# STM32H755_CM4 register map
File version: 2.5
CPU: CM4 r0p1, little endian, MPU, FPU, 4 interrupt priority bits
Registers are 32-bit, read-write, reset 0x0 unless marked. A register's access mark holds for its fields unless they carry their own. Offsets are from the block's base; [hi:lo] are bit positions; lines under a group give offsets from that group; {n}, {i} and the like mark numbered series; 'fields as' and 'values as' point back to an identical list.

## TIM6 — Basic timers
Base 0x40001000
Same registers: TIM7 0x40001400
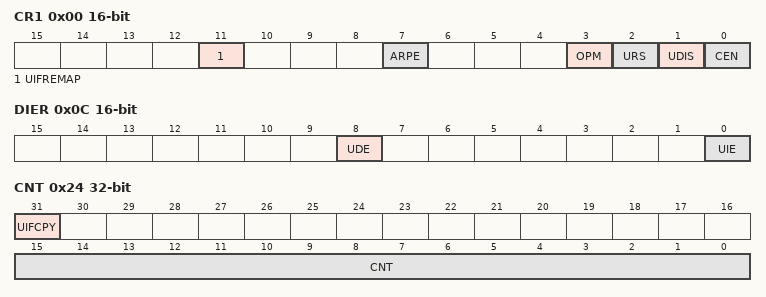
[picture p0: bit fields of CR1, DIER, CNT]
0x00 CR1 16-bit — control register 1
  [11] UIFREMAP — UIF status bit remapping
  [7] ARPE — Auto-reload preload enable
    0=Disabled (TIMx_APRR register is not buffered); 1=Enabled (TIMx_APRR register is buffered)
  [3] OPM — One-pulse mode
    0=Disabled (Counter is not stopped at update event); 1=Enabled (Counter stops counting at the next update event (clearing the CEN bit))
  [2] URS — Update request source
    0=AnyEvent (Any of counter overflow/underflow, setting UG, or update through slave mode, generates an update interrupt or DMA request); 1=CounterOnly (Only counter overflow/underflow generates an update interrupt or DMA request)
  [1] UDIS — Update disable
    0=Enabled (Update event enabled); 1=Disabled (Update event disabled)
  [0] CEN — Counter enable
    0=Disabled (Counter disabled); 1=Enabled (Counter enabled)
0x04 CR2 16-bit — control register 2
  [6:4] MMS — Master mode selection
    0=Reset (Use UG bit from TIMx_EGR register); 1=Enable (Use CNT bit from TIMx_CEN register); 2=Update (Use the update event)
0x0C DIER 16-bit — DMA/Interrupt enable register
  [8] UDE — Update DMA request enable
    0=Disabled (Update DMA request disabled); 1=Enabled (Update DMA request enabled)
  [0] UIE — Update interrupt enable
    0=Disabled (Update interrupt disabled); 1=Enabled (Update interrupt enabled)
0x10 SR 16-bit — status register
  [0] UIF write-0-clears — Update interrupt flag
    on read: 0=NoUpdateOccurred; 1=UpdatePending (Update interrupt pending) | on write: 0=Clear flag
0x14 EGR wo — event generation register
  [0] UG — Update generation
    1=Update (Re-initializes the timer counter and generates an update of the registers.)
0x24 CNT — counter
  [31] UIFCPY — UIF Copy
  [15:0] CNT — Low counter value
0x24 CNT16 16-bit (alternate view of CNT) — 16-bit counter register
  [15:0] CNT — counter value
0x28 PSC 16-bit — prescaler
  [15:0] PSC — Prescaler value
0x2C ARR 16-bit reset 0xFFFF — auto-reload register
  [15:0] ARR — Low Auto-reload value

## DBGMCU — Microcontroller Debug Unit
Base 0x5C001000
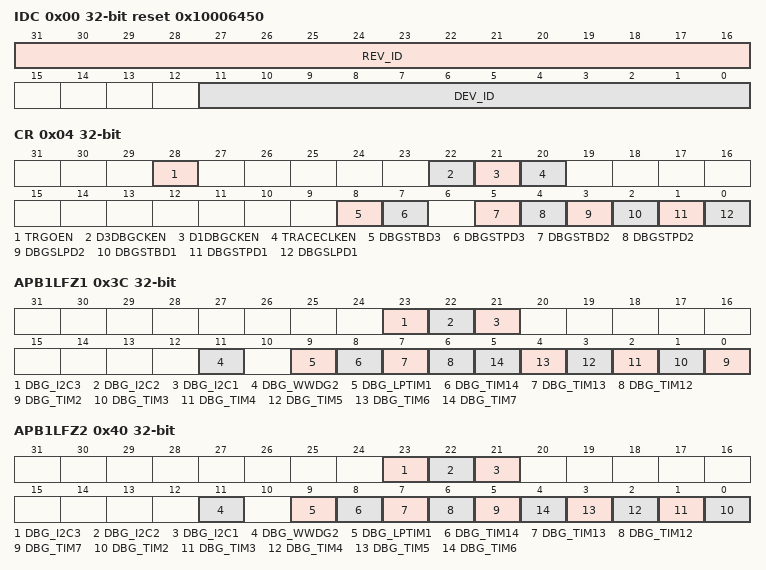
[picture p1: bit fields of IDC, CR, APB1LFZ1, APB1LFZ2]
0x00 IDC ro reset 0x10006450 — DBGMCU Identity Code Register
  [31:16] REV_ID — Revision
  [11:0] DEV_ID — Device ID
0x04 CR — DBGMCU Configuration Register
  [28] TRGOEN — External trigger output enable
  [22] D3DBGCKEN — D3 debug clock enable
  [21] D1DBGCKEN — D1 debug clock enable
  [20] TRACECLKEN — Trace port clock enable
  [8] DBGSTBD3 — Allow debug in D3 Standby mode
  [7] DBGSTPD3 — Allow debug in D3 Stop mode
  [5] DBGSTBD2 — Allow D2 domain debug in Standby mode
  [4] DBGSTPD2 — Allow D2 domain debug in Stop mode
  [3] DBGSLPD2 — Allow D2 domain debug in Sleep mode
  [2] DBGSTBD1 — Allow D1 domain debug in Standby mode
  [1] DBGSTPD1 — Allow D1 domain debug in Stop mode
  [0] DBGSLPD1 — Allow D1 domain debug in Sleep mode
0x34 APB3FZ1 — DBGMCU APB3 peripheral freeze register CPU1
  [6] WWDG1 — WWDG1 stop in debug
0x38 APB3FZ2 — DBGMCU APB3 peripheral freeze register CPU2
  [6] WWDG1 — WWDG1 stop in debug
0x3C APB1LFZ1 — DBGMCU APB1L peripheral freeze register
  [23] DBG_I2C3 — I2C3 SMBUS timeout stop in debug
  [22] DBG_I2C2 — I2C2 SMBUS timeout stop in debug
  [21] DBG_I2C1 — I2C1 SMBUS timeout stop in debug
  [11] DBG_WWDG2 — WWDG2 stop in debug
  [9] DBG_LPTIM1 — LPTIM1 stop in debug
  [8] DBG_TIM14 — TIM14 stop in debug
  [7] DBG_TIM13 — TIM13 stop in debug
  [6] DBG_TIM12 — TIM12 stop in debug
  [n-2] DBG_TIM{n} (n=2..7) — TIM{n} stop in debug
0x40 APB1LFZ2 — DBGMCU APB1L peripheral freeze register CPU2
  [23] DBG_I2C3 — I2C3 SMBUS timeout stop in debug
  [22] DBG_I2C2 — I2C2 SMBUS timeout stop in debug
  [21] DBG_I2C1 — I2C1 SMBUS timeout stop in debug
  [11] DBG_WWDG2 — WWDG2 stop in debug
  [9] DBG_LPTIM1 — LPTIM1 stop in debug
  [8] DBG_TIM14 — TIM14 stop in debug
  [7] DBG_TIM13 — TIM13 stop in debug
  [6] DBG_TIM12 — TIM12 stop in debug
  [5] DBG_TIM7 — TIM4 stop in debug
  [n-2] DBG_TIM{n} (n=2..6) — TIM{n} stop in debug
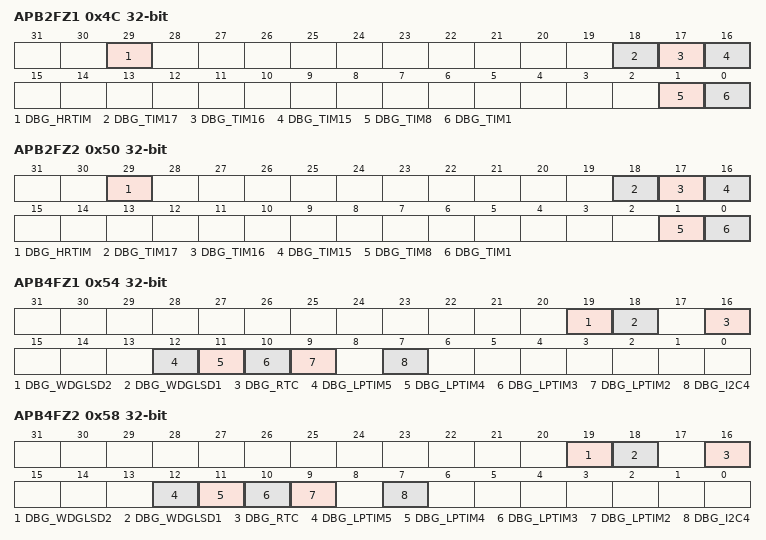
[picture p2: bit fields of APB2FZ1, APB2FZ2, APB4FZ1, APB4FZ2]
0x4C APB2FZ1 — DBGMCU APB2 peripheral freeze register
  [29] DBG_HRTIM — HRTIM stop in debug
  [18] DBG_TIM17 — TIM17 stop in debug
  [17] DBG_TIM16 — TIM16 stop in debug
  [16] DBG_TIM15 — TIM15 stop in debug
  [1] DBG_TIM8 — TIM8 stop in debug
  [0] DBG_TIM1 — TIM1 stop in debug
0x50 APB2FZ2 — DBGMCU APB2 peripheral freeze register CPU2
  fields as APB2FZ1
0x54 APB4FZ1 — DBGMCU APB4 peripheral freeze register
  [19] DBG_WDGLSD2 — Independent watchdog for D2 stop in debug
  [18] DBG_WDGLSD1 — Independent watchdog for D1 stop in debug
  [16] DBG_RTC — RTC stop in debug
  [12] DBG_LPTIM5 — LPTIM5 stop in debug
  [11] DBG_LPTIM4 — LPTIM4 stop in debug
  [10] DBG_LPTIM3 — LPTIM2 stop in debug
  [9] DBG_LPTIM2 — LPTIM2 stop in debug
  [7] DBG_I2C4 — I2C4 SMBUS timeout stop in debug
0x58 APB4FZ2 — DBGMCU APB4 peripheral freeze register CPU2
  [19] DBG_WDGLSD2 — LS watchdog for D2 stop in debug
  [18] DBG_WDGLSD1 — LS watchdog for D1 stop in debug
  [16] DBG_RTC — RTC stop in debug
  [12] DBG_LPTIM5 — LPTIM5 stop in debug
  [11] DBG_LPTIM4 — LPTIM4 stop in debug
  [10] DBG_LPTIM3 — LPTIM2 stop in debug
  [9] DBG_LPTIM2 — LPTIM2 stop in debug
  [7] DBG_I2C4 — I2C4 SMBUS timeout stop in debug

## RAMECC1 — ECC controller is associated to each RAM area
Base 0x52009000
Same registers: RAMECC2 0x48023000
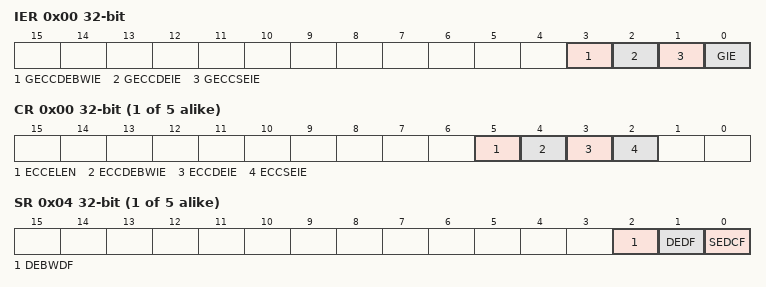
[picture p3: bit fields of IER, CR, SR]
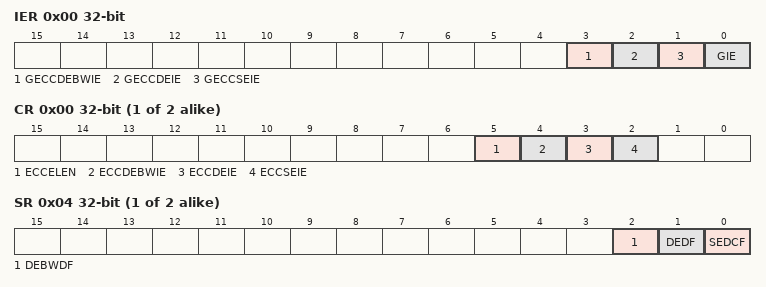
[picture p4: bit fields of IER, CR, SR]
0x00 IER — RAMECC interrupt enable register
  [3] GECCDEBWIE — Global ECC double error on byte write (BW) interrupt enable
  [2] GECCDEIE — Global ECC double error interrupt enable
  [1] GECCSEIE — Global ECC single error interrupt enable
  [0] GIE — Global interrupt enable
{0x0+0x20*i} M{i} (i=1..5) group — Cluster M{i}, containing M?CR, M?SR, M?FAR, M?FDRL, M?FDRH, M?FECR
  0x00 CR — RAMECC monitor x configuration register
    [5] ECCELEN — ECC error latching enable
    [4] ECCDEBWIE — ECC double error on byte write (BW) interrupt enable
    [3] ECCDEIE — ECC double error interrupt enable
    [2] ECCSEIE — ECC single error interrupt enable
  0x04 SR — RAMECC monitor x status register
    [2] DEBWDF — ECC double error on byte write (BW) detected flag
    [1] DEDF — ECC double error detected flag
    [0] SEDCF — ECC single error detected and corrected flag
  0x08 FAR — RAMECC monitor x failing address register
    [31:0] FADD — ECC error failing address
  0x0C FDRL — RAMECC monitor x failing data low register
    [31:0] FDATAL — Failing data low
  0x10 FDRH — RAMECC monitor x failing data high register
    [31:0] FDATAH — Failing data high (64-bit memory)
  0x14 FECR ro — RAMECC monitor x failing ECC error code register
    [31:0] FEC — Failing error code Failing error code

## RAMECC3 — ECC controller is associated to each RAM area
Base 0x58027000
0x00 IER — RAMECC interrupt enable register
  [3] GECCDEBWIE — Global ECC double error on byte write (BW) interrupt enable
  [2] GECCDEIE — Global ECC double error interrupt enable
  [1] GECCSEIE — Global ECC single error interrupt enable
  [0] GIE — Global interrupt enable
{0x0+0x20*i} M{i} (i=1..2) group — Cluster M{i}, containing M?CR, M?SR, M?FAR, M?FDRL, M?FDRH, M?FECR
  0x00 CR — RAMECC monitor x configuration register
    [5] ECCELEN — ECC error latching enable
    [4] ECCDEBWIE — ECC double error on byte write (BW) interrupt enable
    [3] ECCDEIE — ECC double error interrupt enable
    [2] ECCSEIE — ECC single error interrupt enable
  0x04 SR — RAMECC monitor x status register
    [2] DEBWDF — ECC double error on byte write (BW) detected flag
    [1] DEDF — ECC double error detected flag
    [0] SEDCF — ECC single error detected and corrected flag
  0x08 FAR — RAMECC monitor x failing address register
    [31:0] FADD — ECC error failing address
  0x0C FDRL — RAMECC monitor x failing data low register
    [31:0] FDATAL — Failing data low
  0x10 FDRH — RAMECC monitor x failing data high register
    [31:0] FDATAH — Failing data high (64-bit memory)
  0x14 FECR ro — RAMECC monitor x failing ECC error code register
    [31:0] FEC — Failing error code Failing error code

## ART — accelerator - control register (ART_CTR)
Base 0x40024400
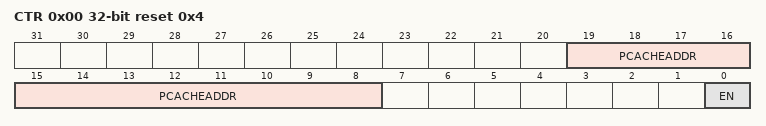
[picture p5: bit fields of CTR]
0x00 CTR reset 0x4 — control register
  [19:8] PCACHEADDR — Cacheable page index
  [0] EN — Cache enable
